# ADuCM410 register map
Vendor: Analog Devices; Series: ADuCM410; File version: 1p0
CPU: CM33 r0p1, little endian, MPU, FPU, 3 interrupt priority bits
Registers are 32-bit, read-write, reset 0x0 unless marked. A register's access mark holds for its fields unless they carry their own. Offsets are from the block's base; [hi:lo] are bit positions; {n}, {i} and the like mark numbered series; 'fields as' and 'values as' point back to an identical list.

## GPTH0
Base 0x40000C00
Same registers: GPTH1 0x40001000
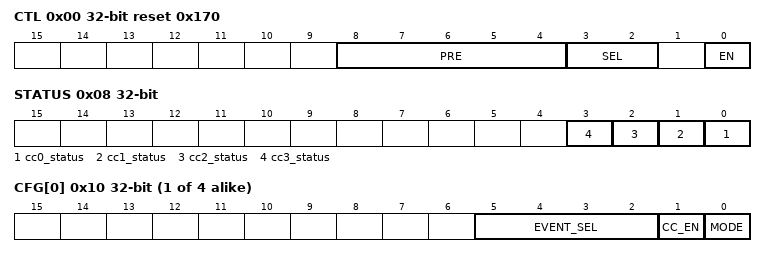
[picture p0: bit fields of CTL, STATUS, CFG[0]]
0x00 CTL reset 0x170 — Timer Control
  [8:4] PRE range 0x00000000..0x0000001F — Timer Prescale
  [3:2] SEL — Clock Source Select
    0=PCLK; 1=SYSCLK (HCLK); 2=LFOSC (High Frequency Oscillator); 3=HFXSTAL (High Frequency XTALL)
  [0] EN range 0x00000000..0x00000001 — Timer Enable
0x04 CNT — Count Value
  [31:0] CNT range 0x00000000..0xFFFFFFFF — Current Counter Value.
0x08 STATUS — Timer Status
  [n] cc{n}_status range 0x00000000..0x00000001 (n=0..3)
{0x10+4i} CFG[{i}] (i=0..3) — Capture Compare Configuration
  [5:2] EVENT_SEL range 0x00000000..0x0000000F — Capture Events Select
  [1] CC_EN range 0x00000000..0x00000001 — Capture Compare Enabled
  [0] MODE — Capture or Compare Mode
    0=CMP (Compare); 1=CAP (Capture)
{0x20+4i} CC[{i}] (i=0..3) — Compare and Capture Value
  [31:0] CC range 0x00000000..0xFFFFFFFF — Capture or Compare Value

## MISC16
Base 0x40002000
0x20 ADIID reset 0x4144
  [15:0] ADIID ro
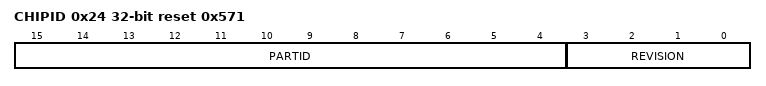
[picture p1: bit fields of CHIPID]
0x24 CHIPID reset 0x571
  [15:4] PARTID ro — Part Identifier
  [3:0] REVISION ro — Silicon Revision Number
0x134 USERKEY — Open to Customer to Protect Important Registers
  [31:0] KEY wo range 0x00000000..0xFFFFFFFF — User Key

## WDT
Base 0x40004000
0x00 LD reset 0x1000 — Watchdog Timer Load Value
  [15:0] LOAD range 0x00000000..0x0000FFFF — WDT Load Value
0x04 VALS reset 0x1000 — Current Count Value
  [15:0] CCOUNT ro — Current WDT Count Value.
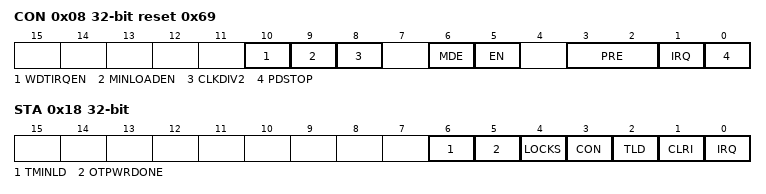
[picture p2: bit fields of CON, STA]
0x08 CON reset 0x69 — Watchdog Timer Control Register
  [10] WDTIRQEN range 0x00000000..0x00000001 — WDT Interrupt Enable
  [9] MINLOADEN range 0x00000000..0x00000001 — Timer Window Control
  [8] CLKDIV2 range 0x00000000..0x00000001 — Clock Source
  [6] MDE — Timer Mode Select
    0=FREE (Free-running Mode); 1=PERIODIC (Periodic Mode (default))
  [5] EN range 0x00000000..0x00000001 — Timer Enable
  [3:2] PRE — Prescaler.
    0=DIV1 (Source Clock/1); 1=DIV16 (Source Clock/16.); 2=DIV256 (Source Clock/256 (default).); 3=DIV4096 (Source Clock/4096)
  [1] IRQ — WDT Interrupt Enable
    0=RESET (Watchdog Timer Timeout Creates a Reset.); 1=INTERRUPT (Watchdog Timer Timeout Creates an Interrupt Instead of Reset.)
  [0] PDSTOP — Power Down Stop Enable
    0=CONTINUE (Continue Counting When in Hibernate); 1=STOPED (Stop Counter When in Hibernate.)
0x0C CLRI — Refresh Watchdog Register
  [15:0] CLRWDG wo range 0x00000000..0x0000FFFF — Refresh Register
0x18 STA — Timer Status
  [6] TMINLD ro — WDTMINLD Write Status
  [5] OTPWRDONE ro — Reset Type Status
  [4] LOCKS ro — Lock Status
    0=OPENED (Timer Operation Not Locked); 1=LOCKED (Timer Enabled and Locked)
  [3] CON ro — WDTCON Write Status
  [2] TLD ro — WDTVAL Write Status
  [1] CLRI ro — WDTCLRI Write Status
  [0] IRQ ro — WDT Interrupt
    0=CLEARED (Watchdog Timer Interrupt Not Pending); 1=PENDING (Watchdog Timer Interrupt Pending)
0x1C MINLD reset 0x800 — Minimum Load Value
  [15:0] MINLOAD range 0x00000000..0x0000FFFF — WDT Min Load Value

## ALLON
Base 0x40005000
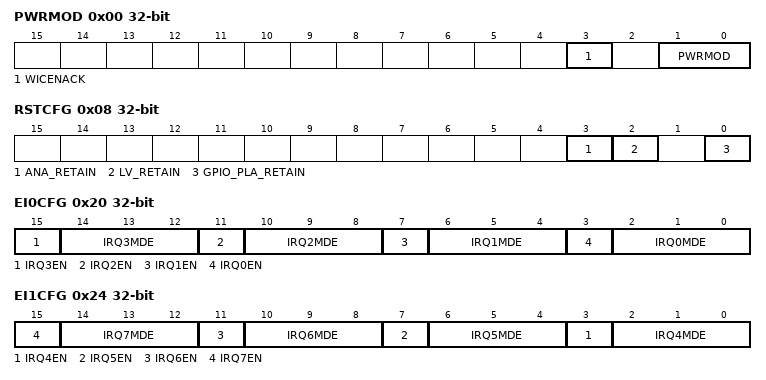
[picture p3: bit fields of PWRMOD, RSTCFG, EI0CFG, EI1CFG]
0x00 PWRMOD — Power Modes
  [3] WICENACK ro — WIC Acknowledgment for SLEEPDEEP
    0=NOACK (Unknown); 1=ACK (Unknown)
  [1:0] PWRMOD — Power Modes Control Bits
    0=FULLACTIVE (Active Mode); 1=CORESLEEP (CORE_SLEEP Mode); 2=SYSSLEEP (SYS_SLEEP Mode); 3=HIBERNATE (Hibernate Mode)
0x04 PWRKEY — Key Protection for PWRMOD
  [15:0] PWRKEY range 0x00000000..0x0000FFFF — Power Control Key Register
0x08 RSTCFG — Reset Configuration
  [3] ANA_RETAIN — Analog Block Retain Status After Watchdog or Software Reset
    0=DIS (GPIO/PLA Retain Status After Watchdog or Software Reset.); 1=EN (GPIO/PLA not Retain Status After Watchdog or Software Reset)
  [2] LV_RETAIN — LV Die Retain Status After Watchdog or Software Reset
    0=DIS (LV Die Retain Status After Watchdog or Software Reset.); 1=EN (LV Die not Retain Status After Watchdog or Software Reset)
  [0] GPIO_PLA_RETAIN — GPIO/PLA Retain Their Status After WDT and Software Reset
    values as ANA_RETAIN
0x0C RSTKEY — Key Protection for RSTCFG
  [15:0] RSTKEY — Reset Configuration Key Register
0x20 EI0CFG — External Interrupt Configuration 0
  [15] IRQ3EN — External Interrupt 3 Enable Bit
    0=DIS (External Interrupt 3 Disabled); 1=EN (External Interrupt 3 Enabled)
  [4n+2:4n] IRQ{n}MDE (n=0..3) — External Interrupt {n} Mode Registers
    0=RISE (Rising Edge); 1=FALL (Falling Edge); 2=RISEORFALL (Rising or Falling Edge); 3=HIGHLEVEL; 4=LOWLEVEL; 5=FALLAUX (Falling Edge (same as 001)); 6=RISEORFALLAUX (Rising or Falling Edge (same as 010)); 7=HIGHLEVELAUX (High Level (same as 011))
  [11] IRQ2EN — External Interrupt 2 Enable Bit
    0=DIS (External Interrupt 2 Disabled); 1=EN (External Interrupt 2 Enabled)
  [7] IRQ1EN — External Interrupt 1 Enable Bit
    0=DIS (External Interrupt 0 Disabled); 1=EN (External Interrupt 0 Enabled)
  [3] IRQ0EN — External Interrupt 0 Enable Bit
    values as IRQ1EN
0x24 EI1CFG — External Interrupt Configuration 1
  [4n-13] IRQ{n}EN (n=4..7) — External Interrupt {n} Enable Bit
    0=DIS (External Interrupt {n} Disabled); 1=EN (External Interrupt {n} Enabled)
  [14:12] IRQ7MDE — External Interrupt 7 Mode Registers
    values as EI0CFG.IRQ0MDE
  [10:8] IRQ6MDE — External Interrupt 6 Mode Registers
    values as EI0CFG.IRQ0MDE
  [6:4] IRQ5MDE — External Interrupt 5 Mode Registers
    0=RISING (Rising Edge); 1=FALLING (Falling Edge); 2=RISEORFALL (Rising or Falling Edge); 3=HIGHLEVEL; 4=LOWLEVEL; 5=FALLAUX (Falling Edge (same as 001)); 6=RISEORFALLAUX (Rising or Falling Edge (same as 010)); 7=HIGHLEVELAUX (High Level (same as 011))
  [2:0] IRQ4MDE — External Interrupt 4 Mode Registers
    values as EI0CFG.IRQ0MDE
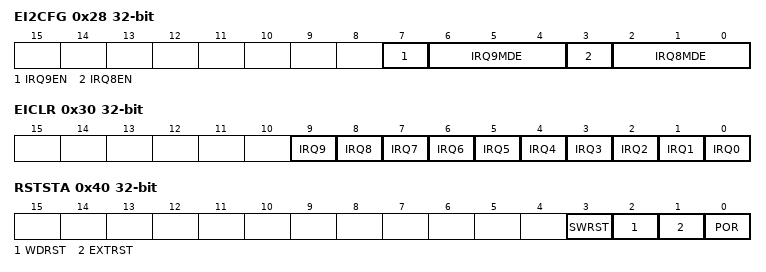
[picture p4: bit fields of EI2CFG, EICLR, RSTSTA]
0x28 EI2CFG — External Interrupt Configuration 2
  [7] IRQ9EN — External Interrupt 8 Enable Bit
    0=DIS (External Interrupt 8 Disabled); 1=EN (External Interrupt 8 Enabled)
  [6:4] IRQ9MDE — External Interrupt 8 Mode Registers
    values as EI0CFG.IRQ0MDE
  [3] IRQ8EN — External Interrupt 8 Enable Bit
    values as IRQ9EN
  [2:0] IRQ8MDE — External Interrupt 8 Mode Registers
    values as EI0CFG.IRQ0MDE
0x30 EICLR — External Interrupt Clear
  [all] fields
    0=NOTCLR (Unknown); 1=CLR (Unknown)
  [n] IRQ{n} (n=0..9) — External Interrupt {n}
0x40 RSTSTA — Reset Status
  [3] SWRST range 0x00000000..0x00000001 — Software Reset
  [2] WDRST range 0x00000000..0x00000001 — Watchdog Timeout
  [1] EXTRST range 0x00000000..0x00000001 — External Reset
  [0] POR range 0x00000000..0x00000001 — Power-on Reset
